AUTOSAR XML (schema 00050)
package /FCADT/ComponentTypes
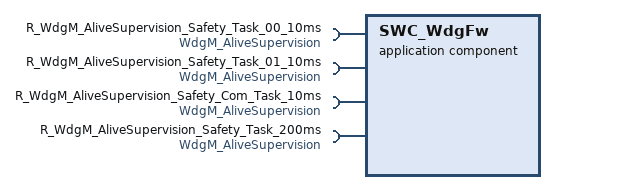
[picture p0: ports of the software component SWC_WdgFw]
  application sw component type SWC_WdgFw
    4 x require port, all with client-com-spec=CheckpointReached, required-interface=WdgM_AliveSupervision:
      R_WdgM_AliveSupervision_Safety_Task_00_10ms
      R_WdgM_AliveSupervision_Safety_Task_01_10ms
      R_WdgM_AliveSupervision_Safety_Com_Task_10ms
      R_WdgM_AliveSupervision_Safety_Task_200ms
    behavior SWC_WdgFw_InternalBehavior
      6 x timing event:
        TMT_Runnable: start-on-event=WdgFw_10ms, period=0.01
        TMT_WdgFw_Safety_Task_00_10ms_CP_10ms: start-on-event=WdgFw_Safety_Task_00_10ms_CP_10ms, period=0.01
        TMT_WdgFw_Safety_Task_01_10ms_CP_10ms: start-on-event=WdgFw_Safety_Task_01_10ms_CP_10ms, period=0.01
        TMT_WdgM_MainFunction_Call_Cntr_10ms: start-on-event=WdgM_MainFunction_Call_Cntr_10ms, period=0.01
        TMT_WdgFw_Safety_Task_Com_10ms_CP_10ms: start-on-event=WdgFw_Safety_Task_Com_10ms_CP_10ms, period=0.01
        TMT_WdgFw_Safety_Task_200ms_CP_200ms: start-on-event=WdgFw_Safety_Task_200ms_CP_200ms, period=0.2
      6 x runnable:
        WdgFw_10ms
          4 x sync call:
            SC_R_WdgM_AliveSupervision_Safety_Task_00_10ms_CheckpointReached: operation=R_WdgM_AliveSupervision_Safety_Task_00_10ms.CheckpointReached, timeout=0
            SC_R_WdgM_AliveSupervision_Safety_Task_01_10ms_CheckpointReached: operation=R_WdgM_AliveSupervision_Safety_Task_01_10ms.CheckpointReached, timeout=0
            SC_R_WdgM_AliveSupervision_Safety_Com_Task_10ms_CheckpointReached: operation=R_WdgM_AliveSupervision_Safety_Com_Task_10ms.CheckpointReached
            SC_R_WdgM_AliveSupervision_Safety_Task_200ms_CheckpointReached: operation=R_WdgM_AliveSupervision_Safety_Task_200ms.CheckpointReached
        WdgFw_Safety_Task_00_10ms_CP_10ms
        WdgFw_Safety_Task_01_10ms_CP_10ms
        WdgM_MainFunction_Call_Cntr_10ms
        WdgFw_Safety_Task_Com_10ms_CP_10ms
        WdgFw_Safety_Task_200ms_CP_200ms
  swc implementation SWC_WdgFw_Implementation: behavior=SWC_WdgFw_InternalBehavior
    code-descriptors:
      code Default: artifact-descriptors=autosar-engineering-object=category=SWSRC
